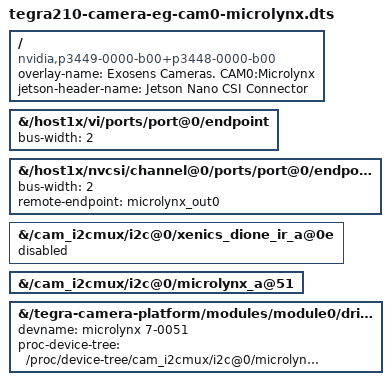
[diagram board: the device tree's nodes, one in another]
// SPDX-License-Identifier: GPL-2.0-only

/dts-v1/;
/plugin/;

/ {
	overlay-name = "Exosens Cameras. CAM0:Microlynx";
	jetson-header-name = "Jetson Nano CSI Connector";
	compatible = "nvidia,p3449-0000-b00+p3448-0000-b00", "nvidia,p3449-0000-b00+p3448-0002-b00";

	fragment@10 {
		target-path = "/host1x/vi/ports/port@0/endpoint";
		__overlay__ {
			bus-width=<2>;
		};
	};

	fragment@11 {
		target-path = "/host1x/nvcsi/channel@0/ports/port@0/endpoint@0";
		__overlay__ {
			bus-width=<2>;
			remote-endpoint = <&microlynx_out0>;
		};
	};

	// Disable Dione cameras
	fragment@12 {
		target-path = "/cam_i2cmux/i2c@0/xenics_dione_ir_a@0e";
		__overlay__ {
			status = "disabled";
		};
	};

	// Enable Microlynx
	fragment@13 {
		target-path = "/cam_i2cmux/i2c@0/microlynx_a@51";
		__overlay__ {
			status = "okay";
		};
	};

	fragment@14 {
		target-path = "/tegra-camera-platform/modules/module0/drivernode0";
		__overlay__ {
			devname = "microlynx 7-0051";
			proc-device-tree = "/proc/device-tree/cam_i2cmux/i2c@0/microlynx_a@51";
		};
	};

};
